# WLR089U0 register map
Vendor: Microchip
Registers are 32-bit, read-write, reset 0x0 unless marked. A register's access mark holds for its fields unless they carry their own. Addresses are absolute, and some are shared; only a register's first bit layout is shown; [hi:lo] are bit positions; {n}, {i} and the like mark numbered series.

## SFR
0xE000E004 ICTR ro reset not defined — Interrupt Controller Type Register (power-on value xxxxxxxxxxxxxxxxxxxxxxxxxxxxxxxx)
  [3:0] INTLINESNUM — Number of interrupt lines supported by NVIC in granularities of 32.

## SysTick
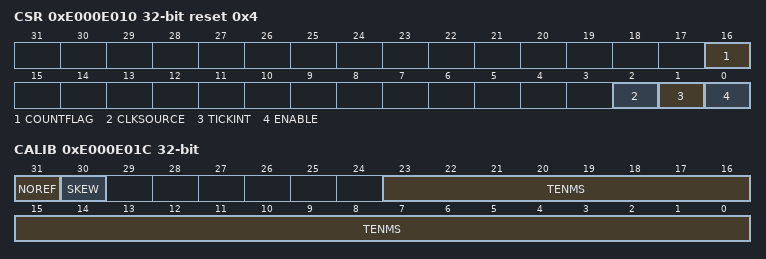
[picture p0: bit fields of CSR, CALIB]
0xE000E010 CSR reset 0x4
  [16] COUNTFLAG — Timer counted to 0 since last read of register
  [2] CLKSOURCE — Clock Source 0=external, 1=processor
    0=External clock; 1=Processor clock
  [1] TICKINT — SysTick Exception Request Enable
    0=Counting down to 0 does not assert the SysTick exception request; 1=Counting down to 0 asserts the SysTick exception request
  [0] ENABLE — SysTick Counter Enable
    0=Counter disabled; 1=Counter enabled
0xE000E014 RVR reset not defined
  [23:0] RELOAD — Value to load into the SysTick Current Value Register when the counter reaches 0
0xE000E018 CVR reset not defined
  [23:0] CURRENT — Current value at the time the register is accessed
0xE000E01C CALIB ro
  [31] NOREF — No Separate Reference Clock
    0=The reference clock is provided; 1=The reference clock is not provided
  [30] SKEW — TENMS is rounded from non-integer ratio
    0=10ms calibration value is exact; 1=10ms calibration value is inexact, because of the clock frequency
  [23:0] TENMS — Reload value to use for 10ms timing

## NVIC
0xE000E100 ISER
  [28:0] SETENA — Interrupt set enable bits
0xE000E180 ICER
  [28:0] CLRENA — Interrupt clear-enable bits
0xE000E200 ISPR
  [28:0] SETPEND — Interrupt set-pending bits
0xE000E280 ICPR
  [28:0] CLRPEND — Interrupt clear-pending bits
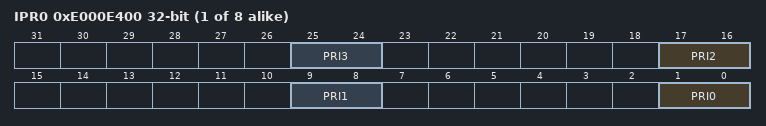
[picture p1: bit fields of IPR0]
{0xE000E400+4i} IPR{i} (i=0..7)
  [8n+1:8n] PRI{n} (n=0..3) — Priority of interrupt n

## SystemControl
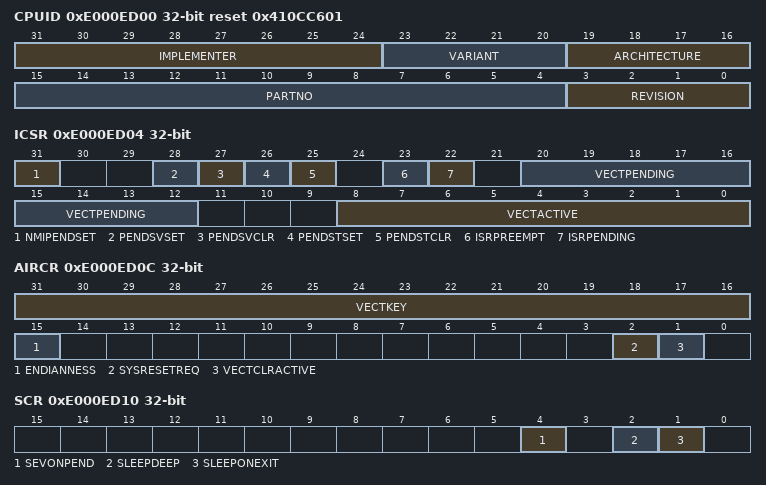
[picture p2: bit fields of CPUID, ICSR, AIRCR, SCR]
0xE000ED00 CPUID ro reset 0x410CC601
  [31:24] IMPLEMENTER — Implementer code, ARM=0x41
  [23:20] VARIANT — Major revision number
  [19:16] ARCHITECTURE — Processor Architecture, 0xC=ARMv6-M
  [15:4] PARTNO — Processor Part Number, 0xC60=Cortex-M0+
  [3:0] REVISION — Minor revision number
0xE000ED04 ICSR
  [31] NMIPENDSET — NMI set-pending bit
    0=Write: no effect; read: NMI exception is not pending; 1=Write: changes NMI exception state to pending; read: NMI exception is pending
  [28] PENDSVSET — PendSV set-pending bit
    0=Write: no effect; read: PendSV exception is not pending; 1=Write: changes PendSV exception state to pending; read: PendSV exception is pending
  [27] PENDSVCLR — PendSV clear-pending bit
    0=No effect; 1=Removes the pending state from the PendSV exception
  [26] PENDSTSET — SysTick exception set-pending bit
    0=Write: no effect; read: SysTick exception is not pending; 1=Write: changes SysTick exception state to pending; read: SysTick exception is pending
  [25] PENDSTCLR — SysTick exception clear-pending bit
    0=No effect; 1=Removes the pending state from the SysTick exception
  [23] ISRPREEMPT — Debug: Pending exception serviced on exit from debug halt
  [22] ISRPENDING — Debug: NVIC interrupt pending
  [20:12] VECTPENDING — Exception number of the highest priority pending enabled exception
  [8:0] VECTACTIVE — Debug: Exception number of currently executing exception, or 0 if thread mode
0xE000ED08 VTOR
  [31:7] TBLOFF — Vector table base offset
0xE000ED0C AIRCR
  [31:16] VECTKEY — Register key (0x05FA)
  [15] ENDIANNESS — Data Endianness, 0=little, 1=big
    0=Little-endian; 1=Big-endian
  [2] SYSRESETREQ — System Reset Request
    0=No system reset request; 1=Asserts a signal to the outer system that requests a reset
  [1] VECTCLRACTIVE — Debug: Clear state information
0xE000ED10 SCR
  [4] SEVONPEND — Send Event on Pending bit
    0=Only enabled interrupts or events can wakeup the processor, disabled interrupts are excluded; 1=Enabled events and all interrupts, including disabled interrupts, can wakeup the processor
  [2] SLEEPDEEP — Uses Deep Sleep as low power mode
    0=Sleep; 1=Deep sleep
  [1] SLEEPONEXIT — Sleep-On-Exit when exiting Handler mode
    0=O not sleep when returning to Thread mode; 1=Enter sleep, or deep sleep, on return from an ISR
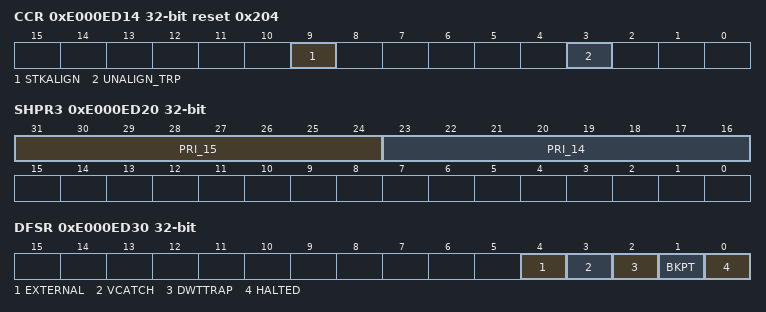
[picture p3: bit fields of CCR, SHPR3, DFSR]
0xE000ED14 CCR ro reset 0x204
  [9] STKALIGN — Stack 8-byte aligned on exception entry
    0=4-byte aligned; 1=8-byte aligned
  [3] UNALIGN_TRP — Unaligned accesses generates a Hard Fault
    0=Do not trap unaligned halfword and word accesses; 1=Trap unaligned halfword and word accesses
0xE000ED1C SHPR2
  [31:24] PRI_11 — Priority of system handler 11, SVCall
0xE000ED20 SHPR3
  [31:24] PRI_15 — Priority of system handler 15, SysTick exception
  [23:16] PRI_14 — Priority of system handler 14, PendSV
0xE000ED24 SHCSR
  [15] SVCALLPENDED
0xE000ED30 DFSR
  [4] EXTERNAL — EDBGRQ debug event
  [3] VCATCH — Vector catch debug event
  [2] DWTTRAP — DWT debug event
  [1] BKPT — Breakpoint debug event
  [0] HALTED — Halt request debug event active
